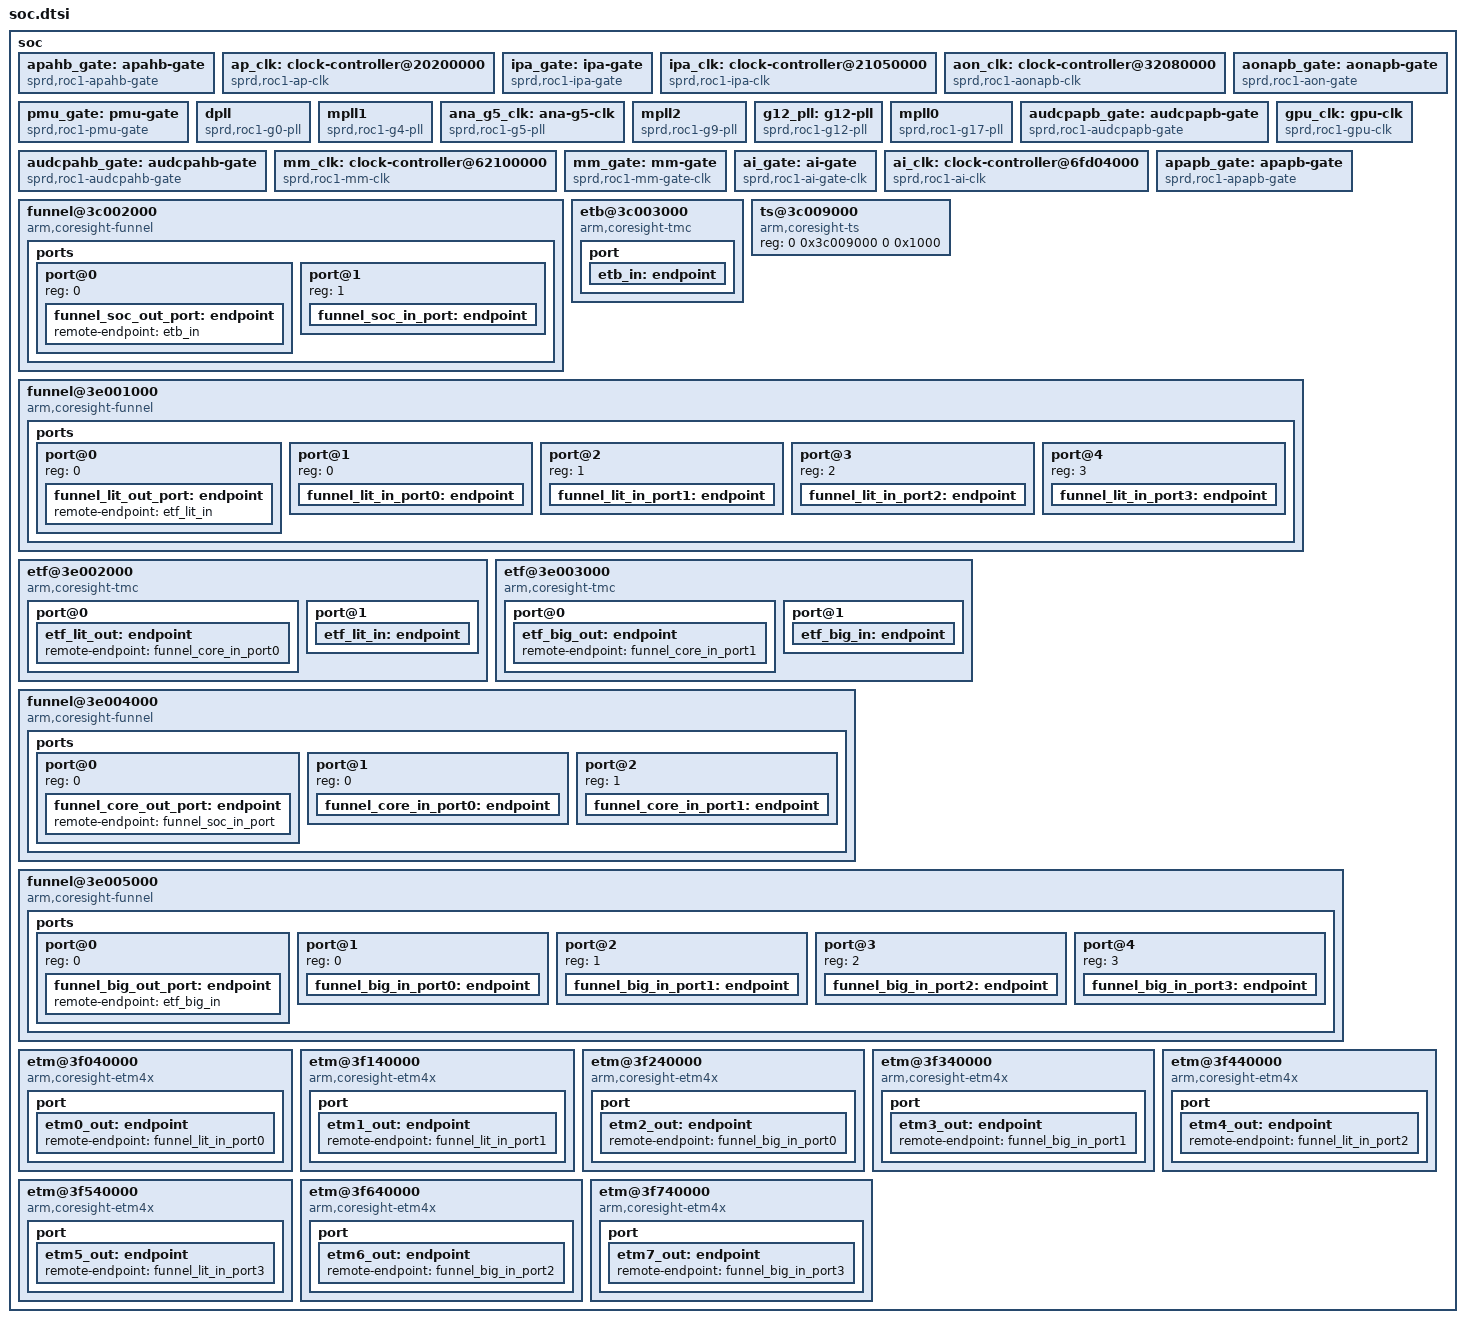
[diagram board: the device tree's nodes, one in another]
/*
 * Spreadtrum Roc1 SoC DTS file
 *
 * Copyright (C) 2018, Spreadtrum Communications Inc.
 *
 * This file is licensed under a dual GPLv2 or X11 license.
 */

	soc {
		apahb_gate: apahb-gate {
			compatible = "sprd,roc1-apahb-gate";
			sprd,syscon = <&ap_ahb_regs>; /* 0x20100000 */
			clocks = <&ext_26m>;
			#clock-cells = <1>;
		};

		ap_clk: clock-controller@20200000 {
			compatible = "sprd,roc1-ap-clk";
			reg = <0 0x20200000 0 0x1000>;
			clocks = <&ext_26m>;
			#clock-cells = <1>;
		};

		ipa_gate: ipa-gate {
			compatible = "sprd,roc1-ipa-gate";
			sprd,syscon = <&ipa_ahb_regs>;
			clocks = <&ext_26m>;
			#clock-cells = <1>;
		};

		ipa_clk: clock-controller@21050000 {
			compatible = "sprd,roc1-ipa-clk";
			reg = <0 0x21050000 0 0x1000>;
			clocks = <&ext_26m>;
			#clock-cells = <1>;
		};

		aon_clk: clock-controller@32080000 {
			compatible = "sprd,roc1-aonapb-clk";
			reg = <0 0x32080000 0 0x1000>;
			clocks = <&ext_26m>;
			#clock-cells = <1>;
		};

		aonapb_gate: aonapb-gate {
			compatible = "sprd,roc1-aon-gate";
			sprd,syscon = <&aon_apb_regs>; /* 0x32090000 */
			clocks = <&ext_26m>;
			#clock-cells = <1>;
		};

		pmu_gate: pmu-gate {
			compatible = "sprd,roc1-pmu-gate";
			sprd,syscon = <&pmu_apb_regs>; /* 0x32280000 */
			clocks = <&ext_26m>;
			#clock-cells = <1>;
		};

		dpll: dpll {
			compatible = "sprd,roc1-g0-pll";
			reg = <0 0x32390000 0 0x3000>; /* 0x32390000 */
			clocks = <&aon_clk CLK_ANALOG_IO_APB>;
			#clock-cells = <1>;
		};

		mpll1: mpll1 {
			compatible = "sprd,roc1-g4-pll";
			sprd,syscon = <&anlg_phy_g4_regs>; /* 0x323c0000 */
			clocks = <&aon_clk CLK_ANALOG_IO_APB>;
			#clock-cells = <1>;
		};

		ana_g5_clk: ana-g5-clk {
			compatible = "sprd,roc1-g5-pll";
			sprd,syscon = <&anlg_phy_g5_regs>; /* 0x323d0000 */
			clocks = <&aon_clk CLK_ANALOG_IO_APB>;
			#clock-cells = <1>;
		};

		mpll2: mpll2 {
			compatible = "sprd,roc1-g9-pll";
			reg = <0 0x32410000 0 0x3000>; /* 0x32410000 */
			clocks = <&aon_clk CLK_ANALOG_IO_APB>;
			#clock-cells = <1>;
		};

		g12_pll: g12-pll {
			compatible = "sprd,roc1-g12-pll";
			reg = <0 0x32414000 0 0x3000>; /* 0x32414000 */
			clocks = <&aon_clk CLK_ANALOG_IO_APB>;
			#clock-cells = <1>;
		};

		mpll0: mpll0 {
			compatible = "sprd,roc1-g17-pll";
			reg = <0 0x32418000 0 0x3000>; /* 0x32418000 */
			clocks = <&aon_clk CLK_ANALOG_IO_APB>;
			#clock-cells = <1>;
		};

		audcpapb_gate: audcpapb-gate {
			compatible = "sprd,roc1-audcpapb-gate";
			sprd,syscon = <&audcp_apb_regs>; /* 0x3350d000 */
			clocks = <&ext_26m>;
			#clock-cells = <1>;
		};

		audcpahb_gate: audcpahb-gate {
			compatible = "sprd,roc1-audcpahb-gate";
			sprd,syscon = <&audcp_ahb_regs>; /* 0x335e0000 */
			clocks = <&ext_26m>;
			#clock-cells = <1>;
		};

		gpu_clk: gpu-clk {
			compatible = "sprd,roc1-gpu-clk";
			sprd,syscon = <&gpu_apb_regs>;	/* 0x60100000 */
			clocks = <&aon_clk CLK_AP_GPU>;
			syscons = <&aon_apb_regs REG_AON_APB_APB_EB0 MASK_AON_APB_GPU_EB>,
				  <&pmu_apb_regs REG_PMU_APB_PD_GPU_TOP_CFG0 MASK_PMU_APB_PD_GPU_TOP_FORCE_SHUTDOWN>;
			syscon-names = "enable", "power";
			#clock-cells = <1>;
		};

		mm_clk: clock-controller@62100000 {
			compatible = "sprd,roc1-mm-clk";
			reg = <0 0x62100000 0 0x1000>;
			clocks = <&aonapb_gate CLK_MM_EB>;
			#clock-cells = <1>;
		};

		mm_gate: mm-gate {
			compatible = "sprd,roc1-mm-gate-clk";
			sprd,syscon = <&mm_ahb_regs>;
			clocks = <&aonapb_gate CLK_MM_EB>;
			syscons = <&aon_apb_regs REG_AON_APB_APB_EB0 MASK_AON_APB_MM_EB>,
				  <&pmu_apb_regs REG_PMU_APB_PD_MM_TOP_CFG MASK_PMU_APB_PD_MM_TOP_FORCE_SHUTDOWN>;
			syscon-names = "enable", "power";
			#clock-cells = <1>;
		};

		ai_gate: ai-gate {
			compatible = "sprd,roc1-ai-gate-clk";
			sprd,syscon = <&ai_apb_regs>;
			clocks = <&aonapb_gate CLK_AI_EB>;
			#clock-cells = <1>;
		};

		ai_clk: clock-controller@6fd04000 {
			compatible = "sprd,roc1-ai-clk";
			reg = <0 0x6fd04000 0 0x1000>;
			clocks = <&ext_26m>;
			syscons = <&aon_apb_regs REG_AON_APB_APB_EB0 MASK_AON_APB_AI_EB>,
				  <&pmu_apb_regs REG_PMU_APB_PD_AI_SYS_CFG MASK_PMU_APB_PD_AI_SYS_FORCE_SHUTDOWN>;
			syscon-names = "enable", "power";
			#clock-cells = <1>;
		};

		apapb_gate: apapb-gate {
			compatible = "sprd,roc1-apapb-gate";
			sprd,syscon = <&ap_apb_regs>; /* 0x71000000 */
			clocks = <&ext_26m>;
			#clock-cells = <1>;
		};

		funnel@3c002000 {
			compatible = "arm,coresight-funnel", "arm,primecell";
			reg = <0 0x3c002000 0 0x1000>;
			clocks = <&ext_26m>;
			clock-names = "apb_pclk";
			ports {
				#address-cells = <1>;
				#size-cells = <0>;

				port@0 {
					reg = <0>;
					funnel_soc_out_port: endpoint {
						remote-endpoint = <&etb_in>;
					};
				};

				port@1 {
					reg = <1>;
					funnel_soc_in_port: endpoint {
						slave-mode;
						remote-endpoint = <&funnel_core_out_port>;
					};
				};
			};
		};

		etb@3c003000 {
			compatible = "arm,coresight-tmc", "arm,primecell";
			reg = <0 0x3c003000 0 0x1000>;
			clocks = <&ext_26m>;
			clock-names = "apb_pclk";
			port {
				etb_in: endpoint {
					slave-mode;
					remote-endpoint = <&funnel_soc_out_port>;
				};
			};
		};

		ts@3c009000 {
			compatible = "arm,coresight-ts", "arm,primecell";
			reg = <0 0x3c009000 0 0x1000>;
		};

		funnel@3e001000 {
			compatible = "arm,coresight-funnel", "arm,primecell";
			reg = <0 0x3e001000 0 0x1000>;
			clocks = <&ext_26m>;
			clock-names = "apb_pclk";

			ports {
				#address-cells = <1>;
				#size-cells = <0>;

				port@0 {
					reg = <0>;
					funnel_lit_out_port: endpoint {
						remote-endpoint = <&etf_lit_in>;
					};
				};

				port@1 {
					reg = <0>;
					funnel_lit_in_port0: endpoint {
						slave-mode;
						remote-endpoint = <&etm0_out>;
					};
				};

				port@2 {
					reg = <1>;
					funnel_lit_in_port1: endpoint {
						slave-mode;
						remote-endpoint = <&etm1_out>;
					};
				};

				port@3 {
					reg = <2>;
					funnel_lit_in_port2: endpoint {
						slave-mode;
						remote-endpoint = <&etm4_out>;
					};
				};

				port@4 {
					reg = <3>;
					funnel_lit_in_port3: endpoint {
						slave-mode;
						remote-endpoint = <&etm5_out>;
					};
				};
			};
		};

		etf@3e002000 {
			compatible = "arm,coresight-tmc", "arm,primecell";
			reg = <0 0x3e002000 0 0x1000>;
			clocks = <&ext_26m>;
			clock-names = "apb_pclk";

			port@0 {
				etf_lit_out: endpoint {
					remote-endpoint = <&funnel_core_in_port0>;
				};
			};

			port@1 {
				etf_lit_in: endpoint {
					slave-mode;
					remote-endpoint = <&funnel_lit_out_port>;
				};
			};
		};

		etf@3e003000 {
			compatible = "arm,coresight-tmc", "arm,primecell";
			reg = <0 0x3e003000 0 0x1000>;
			clocks = <&ext_26m>;
			clock-names = "apb_pclk";

			port@0 {
				etf_big_out: endpoint {
					remote-endpoint = <&funnel_core_in_port1>;
				};
			};

			port@1 {
				etf_big_in: endpoint {
					slave-mode;
					remote-endpoint = <&funnel_big_out_port>;
				};
			};
		};

		funnel@3e004000 {
			compatible = "arm,coresight-funnel", "arm,primecell";
			reg = <0 0x3e004000 0 0x1000>;
			clocks = <&ext_26m>;
			clock-names = "apb_pclk";
			ports {
				#address-cells = <1>;
				#size-cells = <0>;

				port@0 {
					reg = <0>;
					funnel_core_out_port: endpoint {
						remote-endpoint = <&funnel_soc_in_port>;
					};
				};

				port@1 {
					reg = <0>;
					funnel_core_in_port0: endpoint {
						slave-mode;
						remote-endpoint = <&etf_lit_out>;
					};
				};

				port@2 {
					reg = <1>;
					funnel_core_in_port1: endpoint {
						slave-mode;
						remote-endpoint = <&etf_big_out>;
					};
				};
			};
		};

		funnel@3e005000 {
			compatible = "arm,coresight-funnel", "arm,primecell";
			reg = <0 0x3e005000 0 0x1000>;
			clocks = <&ext_26m>;
			clock-names = "apb_pclk";

			ports {
				#address-cells = <1>;
				#size-cells = <0>;

				port@0 {
					reg = <0>;
					funnel_big_out_port: endpoint {
						remote-endpoint = <&etf_big_in>;
					};
				};

				port@1 {
					reg = <0>;
					funnel_big_in_port0: endpoint {
						slave-mode;
						remote-endpoint = <&etm2_out>;
					};
				};

				port@2 {
					reg = <1>;
					funnel_big_in_port1: endpoint {
						slave-mode;
						remote-endpoint = <&etm3_out>;
					};
				};

				port@3 {
					reg = <2>;
					funnel_big_in_port2: endpoint {
						slave-mode;
						remote-endpoint = <&etm6_out>;
					};
				};

				port@4 {
					reg = <3>;
					funnel_big_in_port3: endpoint {
						slave-mode;
						remote-endpoint = <&etm7_out>;
					};
				};
			};
		};

		etm@3f040000 {
			compatible = "arm,coresight-etm4x", "arm,primecell";
			reg = <0 0x3f040000 0 0x1000>;
			cpu = <&CPU0>;
			clocks = <&ext_26m>, <&aon_clk CLK_CSSYS>, <&g12_pll CLK_TWPLL_512M>;
			clock-names = "apb_pclk", "clk_cs", "cs_src";

			port {
				etm0_out: endpoint {
					remote-endpoint = <&funnel_lit_in_port0>;
				};
			};
		};

		etm@3f140000 {
			compatible = "arm,coresight-etm4x", "arm,primecell";
			reg = <0 0x3f140000 0 0x1000>;
			cpu = <&CPU1>;
			clocks = <&ext_26m>, <&aon_clk CLK_CSSYS>, <&g12_pll CLK_TWPLL_512M>;
			clock-names = "apb_pclk", "clk_cs", "cs_src";

			port {
				etm1_out: endpoint {
					remote-endpoint = <&funnel_lit_in_port1>;
				};
			};
		};

		etm@3f240000 {
			compatible = "arm,coresight-etm4x", "arm,primecell";
			reg = <0 0x3f240000 0 0x1000>;
			cpu = <&CPU2>;
			clocks = <&ext_26m>, <&aon_clk CLK_CSSYS>, <&g12_pll CLK_TWPLL_512M>;
			clock-names = "apb_pclk", "clk_cs", "cs_src";

			port {
				etm2_out: endpoint {
					remote-endpoint = <&funnel_big_in_port0>;
				};
			};
		};

		etm@3f340000 {
			compatible = "arm,coresight-etm4x", "arm,primecell";
			reg = <0 0x3f340000 0 0x1000>;
			cpu = <&CPU3>;
			clocks = <&ext_26m>, <&aon_clk CLK_CSSYS>, <&g12_pll CLK_TWPLL_512M>;
			clock-names = "apb_pclk", "clk_cs", "cs_src";

			port {
				etm3_out: endpoint {
					remote-endpoint = <&funnel_big_in_port1>;
				};
			};
		};

		etm@3f440000 {
			compatible = "arm,coresight-etm4x", "arm,primecell";
			reg = <0 0x3f440000 0 0x1000>;
			cpu = <&CPU4>;
			clocks = <&ext_26m>, <&aon_clk CLK_CSSYS>, <&g12_pll CLK_TWPLL_512M>;
			clock-names = "apb_pclk", "clk_cs", "cs_src";

			port {
				etm4_out: endpoint {
					remote-endpoint = <&funnel_lit_in_port2>;
				};
			};
		};

		etm@3f540000 {
			compatible = "arm,coresight-etm4x", "arm,primecell";
			reg = <0 0x3f540000 0 0x1000>;
			cpu = <&CPU5>;
			clocks = <&ext_26m>, <&aon_clk CLK_CSSYS>, <&g12_pll CLK_TWPLL_512M>;
			clock-names = "apb_pclk", "clk_cs", "cs_src";

			port {
				etm5_out: endpoint {
					remote-endpoint = <&funnel_lit_in_port3>;
				};
			};
		};

		etm@3f640000 {
			compatible = "arm,coresight-etm4x", "arm,primecell";
			reg = <0 0x3f640000 0 0x1000>;
			cpu = <&CPU6>;
			clocks = <&ext_26m>, <&aon_clk CLK_CSSYS>, <&g12_pll CLK_TWPLL_512M>;
			clock-names = "apb_pclk", "clk_cs", "cs_src";

			port {
				etm6_out: endpoint {
					remote-endpoint = <&funnel_big_in_port2>;
				};
			};
		};

		etm@3f740000 {
			compatible = "arm,coresight-etm4x", "arm,primecell";
			reg = <0 0x3f740000 0 0x1000>;
			cpu = <&CPU7>;
			clocks = <&ext_26m>, <&aon_clk CLK_CSSYS>, <&g12_pll CLK_TWPLL_512M>;
			clock-names = "apb_pclk", "clk_cs", "cs_src";

			port {
				etm7_out: endpoint {
					remote-endpoint = <&funnel_big_in_port3>;
				};
			};
		};
	};

